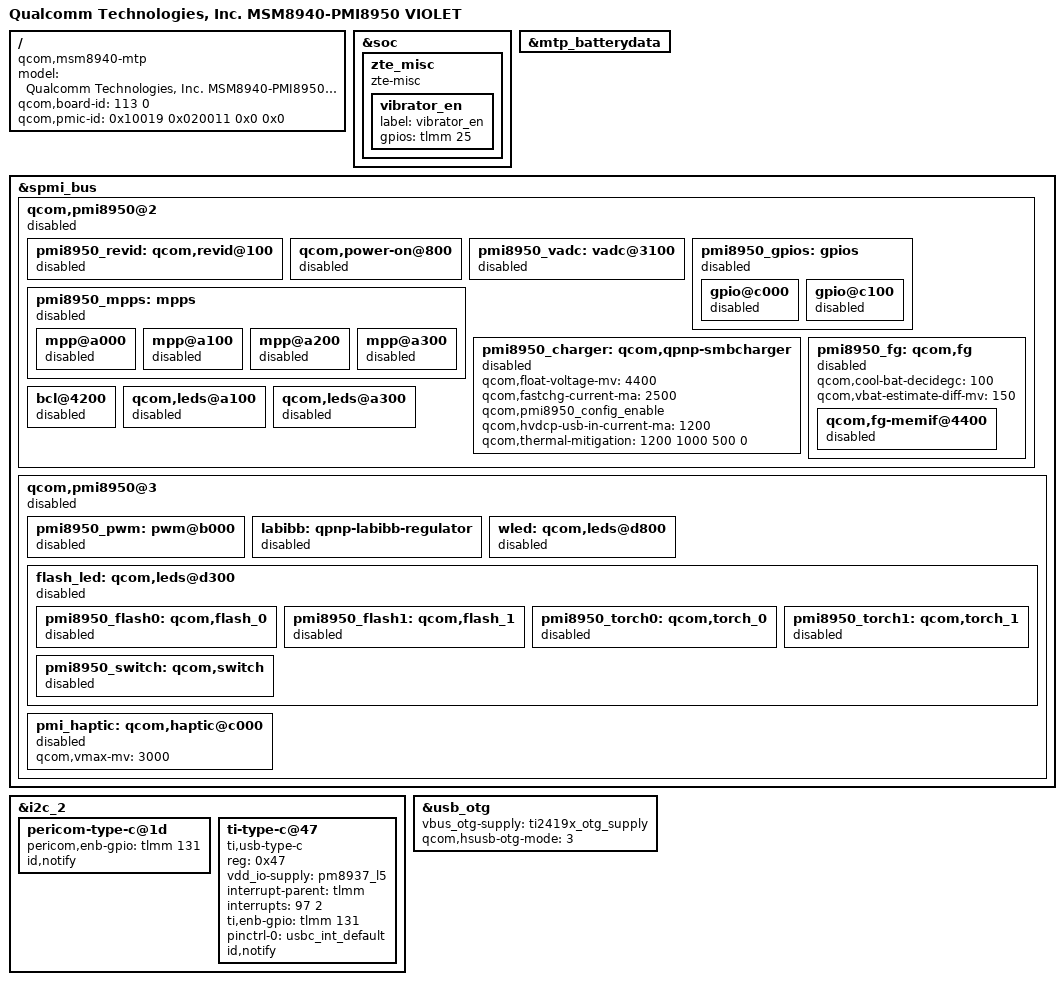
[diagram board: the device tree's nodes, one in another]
/*
 * Copyright (c) 2016, The Linux Foundation. All rights reserved.
 *
 * This program is free software; you can redistribute it and/or modify
 * it under the terms of the GNU General Public License version 2 and
 * only version 2 as published by the Free Software Foundation.
 *
 * This program is distributed in the hope that it will be useful,
 * but WITHOUT ANY WARRANTY; without even the implied warranty of
 * MERCHANTABILITY or FITNESS FOR A PARTICULAR PURPOSE.  See the
 * GNU General Public License for more details.
 */

/dts-v1/;

#include "msm8940.dtsi"
#include "msm8940-pmi8950-mtp.dtsi"
#include "zte-msm8940-violet.dtsi"
#include "msm8940-camera-sensor-zte-violet.dtsi"

/ {
	model = "Qualcomm Technologies, Inc. MSM8940-PMI8950 VIOLET";
	compatible = "qcom,msm8940-mtp", "qcom,msm8940", "qcom,mtp";
	qcom,board-id= <113 0>;
	qcom,pmic-id = <0x10019 0x020011 0x0 0x0>;
};

&soc {
	zte_misc {
		compatible = "zte-misc";
		vibrator_en{
			label = "vibrator_en";
			gpios = <&tlmm 25 0x0>;
		};
	};
};

&pmi8950_charger {
	qcom,float-voltage-mv = <4400>;
	qcom,fastchg-current-ma = <2500>;
	qcom,pmi8950_config_enable;
	qcom,hvdcp-usb-in-current-ma = <1200>;
	qcom,thermal-mitigation = <1200 1000 500 0>;
};
&pmi8950_fg{
	qcom,cool-bat-decidegc = <100>;
	qcom,vbat-estimate-diff-mv = <150>;
};
&pmi_haptic{
	qcom,vmax-mv = <3000>;
};

&mtp_batterydata {
	#include "zte_n9560_3990mah.dtsi"
};

&spmi_bus {
	qcom,pmi8950@2 {
		status = "disabled";

		pmi8950_revid: qcom,revid@100 {
			status = "disabled";
		};

		qcom,power-on@800 {
			status = "disabled";
		};

		pmi8950_vadc: vadc@3100 {
			status = "disabled";
		};

		pmi8950_gpios: gpios {
			status = "disabled";

			gpio@c000 {
				status = "disabled";
			};

			gpio@c100 {
				status = "disabled";
			};
		};

		pmi8950_mpps: mpps {
			status = "disabled";

			mpp@a000 {
				status = "disabled";
			};

			mpp@a100 {
				status = "disabled";
			};

			mpp@a200 {
				status = "disabled";
			};

			mpp@a300 {
				status = "disabled";
			};
		};

		pmi8950_charger: qcom,qpnp-smbcharger {
			status = "disabled";
		};

		pmi8950_fg: qcom,fg {
			status = "disabled";

			qcom,fg-memif@4400 {
				status = "disabled";
			};
		};

		bcl@4200 {
			status = "disabled";
		};

		qcom,leds@a100 {
			status = "disabled";
		};
		qcom,leds@a300 {
			status = "disabled";
		};
	};

	qcom,pmi8950@3 {
		status = "disabled";

		pmi8950_pwm: pwm@b000 {
			status = "disabled";
		};

		labibb: qpnp-labibb-regulator {
			status = "disabled";
		};

		wled: qcom,leds@d800 {
			status = "disabled";
		};

		flash_led: qcom,leds@d300 {
			status = "disabled";

			pmi8950_flash0: qcom,flash_0 {
				status = "disabled";
			};

			pmi8950_flash1: qcom,flash_1 {
				status = "disabled";
			};

			pmi8950_torch0: qcom,torch_0 {
				status = "disabled";
			};

			pmi8950_torch1: qcom,torch_1 {
				status = "disabled";
			};

			pmi8950_switch: qcom,switch {
				status = "disabled";
			};
		};

		pmi_haptic: qcom,haptic@c000 {
			status = "disabled";
		};
	};
};

&i2c_2 {
	pericom-type-c@1d {
		pericom,enb-gpio = <&tlmm 131 0x0>;	/* active high */
		id,notify;
	};

	ti-type-c@47 {
		compatible = "ti,usb-type-c";
		reg = <0x47>;
		vdd_io-supply = <&pm8937_l5>;
		interrupt-parent = <&tlmm>;
		interrupts = <97 2>;  /* TLMM 97, TRIGGER_FALLING */
		ti,enb-gpio = <&tlmm 131 0x0>;	/* active high */
		pinctrl-names = "default";
		pinctrl-0 = <&usbc_int_default>;
		id,notify;
	};
};

&usb_otg {
	vbus_otg-supply = <&ti2419x_otg_supply>;
	qcom,hsusb-otg-mode = <3>; /*OTG mode*/
};
